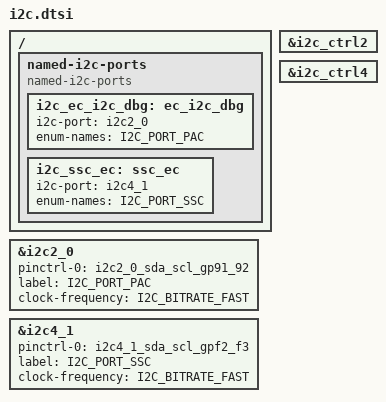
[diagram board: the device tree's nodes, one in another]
/* Copyright 2026 The ChromiumOS Authors
 * Use of this source code is governed by a BSD-style license that can be
 * found in the LICENSE file.
 */

/ {
	named-i2c-ports {
		compatible = "named-i2c-ports";

		i2c_ec_i2c_dbg: ec_i2c_dbg {
			i2c-port = <&i2c2_0>;
			enum-names = "I2C_PORT_PAC";
		};
		i2c_ssc_ec: ssc_ec {
			i2c-port = <&i2c4_1>;
			enum-names = "I2C_PORT_SSC";
		};
	};
};

&i2c2_0 {
	status = "okay";
	pinctrl-0 = <&i2c2_0_sda_scl_gp91_92>;
	pinctrl-names = "default";

	label = "I2C_PORT_PAC";
	clock-frequency = <I2C_BITRATE_FAST>;
};

&i2c4_1 {
	status = "okay";
	pinctrl-0 = <&i2c4_1_sda_scl_gpf2_f3>;
	pinctrl-names = "default";

	label = "I2C_PORT_SSC";
	clock-frequency = <I2C_BITRATE_FAST>;
};

&i2c_ctrl2 {
	status = "okay";
};

&i2c_ctrl4 {
	status = "okay";
};
